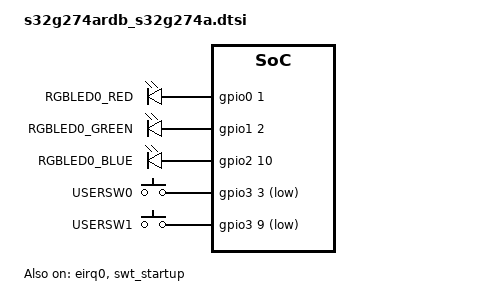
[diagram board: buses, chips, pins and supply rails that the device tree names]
/*
 * Copyright 2025 NXP
 *
 * SPDX-License-Identifier: Apache-2.0
 */

#include <zephyr/dt-bindings/gpio/gpio.h>
#include <zephyr/dt-bindings/input/input-event-codes.h>
#include "s32g274ardb_s32g274a-pinctrl.dtsi"

/ {
	aliases {
		led0 = &user_led_red;
		led1 = &user_led_green;
		led2 = &user_led_blue;
		sw0 = &user_button_0;
		sw1 = &user_button_1;
		watchdog0 = &swt_startup;
	};

	chosen {
		zephyr,canbus = &flexcan0;
	};

	leds {
		compatible = "gpio-leds";

		user_led_red: user_led_red {
			gpios = <&gpio0 1 GPIO_ACTIVE_HIGH>;
			label = "RGBLED0_RED";
		};

		user_led_green: user_led_green {
			gpios = <&gpio1 2 GPIO_ACTIVE_HIGH>;
			label = "RGBLED0_GREEN";
		};

		user_led_blue: user_led_blue {
			gpios = <&gpio2 10 GPIO_ACTIVE_HIGH>;
			label = "RGBLED0_BLUE";
		};
	};

	gpio_keys {
		compatible = "gpio-keys";

		user_button_0: button_0 {
			label = "USERSW0";
			gpios = <&gpio3 3 GPIO_ACTIVE_LOW>;
			zephyr,code = <INPUT_KEY_0>;
		};

		user_button_1: button_1 {
			label = "USERSW1";
			gpios = <&gpio3 9 GPIO_ACTIVE_LOW>;
			zephyr,code = <INPUT_KEY_1>;
		};
	};
};

&gpio0 {
	status = "okay";
};

&gpio1 {
	status = "okay";
};

&gpio2 {
	status = "okay";
};

&gpio3 {
	status = "okay";
};

&eirq0 {
	pinctrl-0 = <&eirq0_default>;
	pinctrl-names = "default";
	status = "okay";
};

&flexcan0 {
	pinctrl-0 = <&flexcan0_default>;
	pinctrl-names = "default";
};

&swt_startup {
	status = "okay";
};
